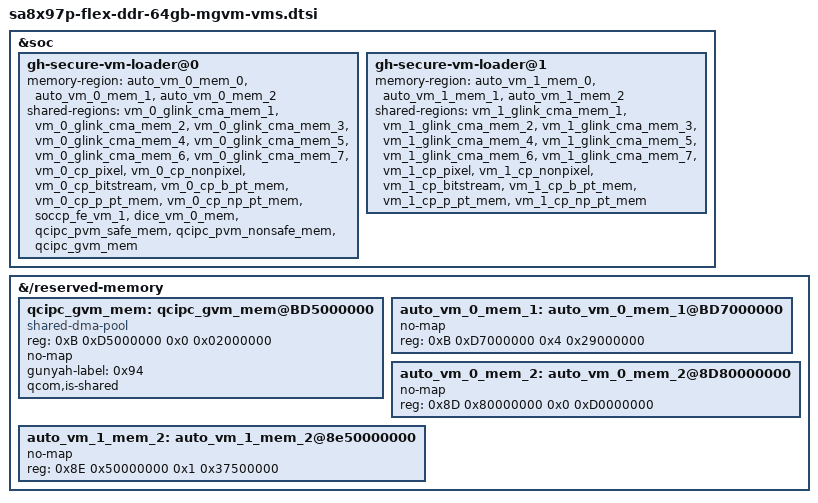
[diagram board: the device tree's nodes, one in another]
// SPDX-License-Identifier: BSD-3-Clause
/*
 * Copyright (c) Qualcomm Technologies, Inc. and/or its subsidiaries.
 */

#include "sa8x97p-vms-mgvm.dtsi"

&soc {
	gh-secure-vm-loader@0 {
		memory-region = <&auto_vm_0_mem_0 &auto_vm_0_mem_1 &auto_vm_0_mem_2>;
		shared-regions = <&vm_0_glink_cma_mem_1
				&vm_0_glink_cma_mem_2
				&vm_0_glink_cma_mem_3
				&vm_0_glink_cma_mem_4
				&vm_0_glink_cma_mem_5
				&vm_0_glink_cma_mem_6
				&vm_0_glink_cma_mem_7
				&vm_0_cp_pixel
				&vm_0_cp_nonpixel
				&vm_0_cp_bitstream
				&vm_0_cp_b_pt_mem
				&vm_0_cp_p_pt_mem
				&vm_0_cp_np_pt_mem
				&soccp_fe_vm_1
				&dice_vm_0_mem
				&qcipc_pvm_safe_mem
				&qcipc_pvm_nonsafe_mem
				&qcipc_gvm_mem>;
	};

	gh-secure-vm-loader@1 {
		memory-region = <&auto_vm_1_mem_0 &auto_vm_1_mem_1 &auto_vm_1_mem_2>;
		shared-regions = <&vm_1_glink_cma_mem_1
				&vm_1_glink_cma_mem_2
				&vm_1_glink_cma_mem_3
				&vm_1_glink_cma_mem_4
				&vm_1_glink_cma_mem_5
				&vm_1_glink_cma_mem_6
				&vm_1_glink_cma_mem_7
				&vm_1_cp_pixel
				&vm_1_cp_nonpixel
				&vm_1_cp_bitstream
				&vm_1_cp_b_pt_mem
				&vm_1_cp_p_pt_mem
				&vm_1_cp_np_pt_mem>;
	};
};

&{/reserved-memory} {
	qcipc_gvm_mem: qcipc_gvm_mem@BD5000000 {
		compatible = "shared-dma-pool";
		reg = <0xB 0xD5000000 0x0 0x02000000>;
		no-map;
		gunyah-label = <0x94>;
		qcom,is-shared;
	};

	auto_vm_0_mem_1: auto_vm_0_mem_1@BD7000000 {
		no-map;
		reg = <0xB 0xD7000000 0x4 0x29000000>; /*17040MB*/
	};

	auto_vm_0_mem_2: auto_vm_0_mem_2@8D80000000 {
		no-map;
		reg = <0x8D 0x80000000 0x0 0xD0000000>; /*3316MB*/
	};

	auto_vm_1_mem_2: auto_vm_1_mem_2@8e50000000 {
		no-map;
		reg = <0x8E 0x50000000 0x1 0x37500000>; /*4981MB*/
	};
};
